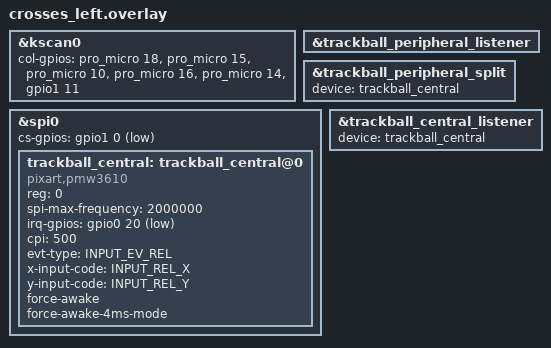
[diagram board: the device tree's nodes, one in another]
#include "crosses.dtsi"
#include <zephyr/dt-bindings/input/input-event-codes.h>

&kscan0 {
  col-gpios
    = <&pro_micro 18 GPIO_ACTIVE_HIGH>
    , <&pro_micro 15 GPIO_ACTIVE_HIGH>
    , <&pro_micro 10 GPIO_ACTIVE_HIGH>
    , <&pro_micro 16 GPIO_ACTIVE_HIGH>
    , <&pro_micro 14 GPIO_ACTIVE_HIGH>
    , <&gpio1 11 GPIO_ACTIVE_HIGH>
    ;
};

&trackball_peripheral_listener {
  status = "okay";
};

/* ZMK v0.3.0: Peripheral input-split requires a 'device' property pointing to the source device */
&trackball_peripheral_split {
  device = <&trackball_central>;
};

&spi0 {
  cs-gpios = <&gpio1 0 GPIO_ACTIVE_LOW>;

  trackball_central: trackball_central@0 {
    status = "okay";
    compatible = "pixart,pmw3610";
    reg = <0>;
    spi-max-frequency = <2000000>;
    irq-gpios = <&gpio0 20 (GPIO_ACTIVE_LOW | GPIO_PULL_UP)>;
    cpi = <500>;
    evt-type = <INPUT_EV_REL>;
    x-input-code = <INPUT_REL_X>;
    y-input-code = <INPUT_REL_Y>;
    force-awake;
    /* keep the sensor awake while ZMK activity state is ACTIVE,
        fallback to normal downshift mode after ZMK goes into IDLE / SLEEP mode.
        thus, the sensor would be a `wakeup-source` */

    force-awake-4ms-mode;
    /* while force-awake is acitvated, enable this mode to force sampling per
        4ms, where the default sampling rate is 8ms. */
    /* NOTE: apply this mode if you need 250Hz with direct USB connection. */
  };
};

// Overrides for the input listener node
&trackball_central_listener {
  status = "okay";
  device = <&trackball_central>;
};
 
